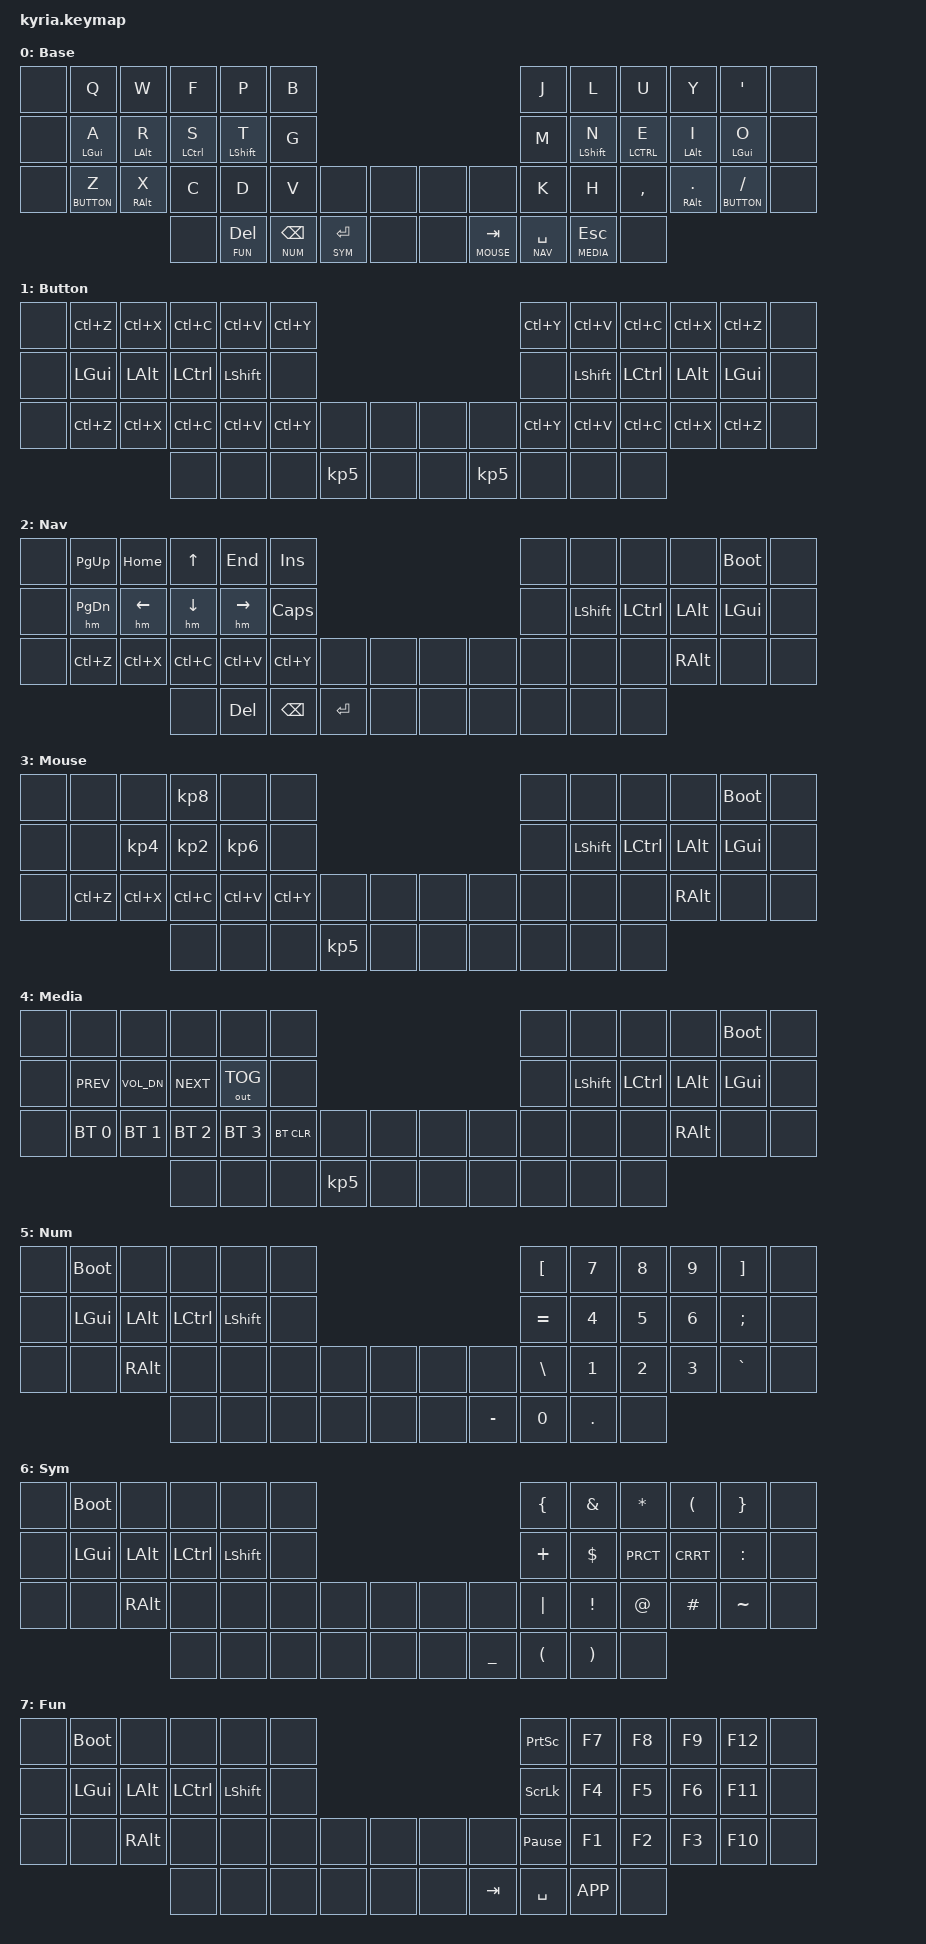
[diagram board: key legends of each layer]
/*
 * Copyright (c) 2020 The ZMK Contributors
 *
 * SPDX-License-Identifier: MIT
 */

#include <behaviors.dtsi>
#include <dt-bindings/zmk/bt.h>
#include <dt-bindings/zmk/keys.h>

// LAYER DEFINITIONS //
#define BASE   0
#define BUTTON 1
#define NAV    2
#define MOUSE  3
#define MEDIA  4
#define NUM    5
#define SYM    6
#define FUN    7

// CUSTOM KEY DEFINITIONS //
#define U_RDO &kp LC(Y) // WINDOWS redo
#define U_PST &kp LC(V) // WINDOWS paste
#define U_CPY &kp LC(C) // WINDOWS copy
#define U_CUT &kp LC(X) // WINDOWS cut
#define U_UND &kp LC(Z) // WINDOWS undo

#define U_BTN1 &kp KP_N5
#define U_BTN2 &none
#define U_BTN3 &none
#define U_MS_D &kp KP_N2
#define U_MS_L &kp KP_N4
#define U_MS_R &kp KP_N6
#define U_MS_U &kp KP_N8
#define U_WH_D &none
#define U_WH_L &none
#define U_WH_R &none
#define U_WH_U &none

// HOME ROW MOD CUSTOMIZATIONS //
#define U_TAPPING_TERM 200
#define U_TIMEOUT 50

/*                            KEY POSITIONS
  ╭─────────────-────────-─╮                 ╭────────────────────────╮
  │  0   1   2   3   4   5 │                 │  6   7   8   9  10  11 │
  │ 12  13  14  15  16  17 ╰───────╮ ╭───────╯ 18  19  20  21  22  23 │
  │ 24  25  26  27  28  29  30  31 │ │ 32  33  34  35  36  37  38  39 │
  ╰───────────╮ 40  41  42  43  44 │ │ 45  46  47  48  49 ╭───────────╯
              ╰────────────────────╯ ╰────────────────────╯            
*/

/ {
  behaviors {
    hm: homerow_mods {
      compatible = "zmk,behavior-hold-tap";
      label = "HOMEROW_MODS";
      #binding-cells = <2>;
      tapping_term_ms = <U_TAPPING_TERM>;
      flavor = "tap-preferred";
      bindings = <&kp>, <&kp>;
    };
  };

  combos {        
        compatible = "zmk,combos";        
        combo_btc {            
            timeout-ms = <U_TIMEOUT>;            
            key-positions = <0 12>;            
            bindings = <&bt BT_CLR>;  
        }; 
        combo_min2 {            
            timeout-ms = <U_TIMEOUT>;            
            key-positions = <3 4>;            
            bindings = <&kp MINUS>;  
        }; 
    
        combo_quot2 { 
            timeout-ms = <U_TIMEOUT>;             
            key-positions = <27 28>;            
            bindings = <&kp QUOT>;  
        };
    };


    keymap {
        compatible = "zmk,keymap";

        BASE_layer {
              label = "Base"; //MIRYOKU_ALTERNATIVES_BASE_COLEMAK_DH_FLIP

            /*                                                  BASE LAYER
            ╭──────────────────────────────────────────╮                         ╭──────────────────────────────────────────╮
            │ NONE  Q         W      F       P       B │                         │ J  L       U       Y      '         NONE │
            │ NONE  A|WIN     R|ALT  S|CTRL  T|SHFT  G ╰───────────╮ ╭───────────╯ M  N|SHFT  E|CTRL  I|ALT  O|WIN     NONE │
            │ NONE  Z|BUTTON  X|ALT  C       D       V  NONE  NONE │ │ NONE  NONE  K  H       ,       .|ALT  /|BUTTON  NONE │
            ╰───────────╮   NONE  DEL|FUN  BSPC|NUM  RET|SYM  NONE │ │ NONE  TAB|MOUSE  SPC|NAV  ESC|MEDIA  NONE ╭──────────╯
                        ╰──────────────────────────────────────────╯ ╰───────────────────────────────────────────╯            
            */

            bindings = <
                &none  &kp Q             &kp W              &kp F              &kp P              &kp B                                                          &kp J               &kp L               &kp U               &kp Y               &kp SQT           &none
                &none  &hm LGUI A        &hm LALT R         &hm LCTRL S        &hm LSHFT T        &kp G                                                          &kp M               &hm LSHFT N         &LCTRL E            &hm LALT I          &hm LGUI O        &none
                &none  &lt BUTTON Z      &hm RALT X         &kp C              &kp D              &kp V         &none        &none     &none      &none          &kp K               &kp H               &kp COMMA           &hm RALT DOT        &lt BUTTON SLASH  &none
                                                            &none              &lt FUN DEL        &lt NUM BSPC  &lt SYM RET  &none     &none      &lt MOUSE TAB  &lt NAV SPC         &lt MEDIA ESC       &none             
            >; 
                                           
        };                                       
        BUTTON_layer {                                       
              label = "Button"; //MIRYOKU_ALTERNATIVES_BUTTON                                      
            bindings = <                                       
                &none  U_UND             U_CUT              U_CPY              U_PST              U_RDO                                                          U_RDO               U_PST               U_CPY               U_CUT               U_UND             &none
                &none  &kp LGUI          &kp LALT           &kp LCTRL          &kp LSHFT          &none                                                          &none               &kp LSHFT           &kp LCTRL           &kp LALT            &kp LGUI          &none
                &none  U_UND             U_CUT              U_CPY              U_PST              U_RDO         &none        &none     &none      &none          U_RDO               U_PST               U_CPY               U_CUT               U_UND             &none
                                                            &none              U_BTN2             U_BTN3        U_BTN1       &none     &none      U_BTN1         U_BTN3              U_BTN2              &none
            >;        
        };  
        NAV_layer {  
            label = "Nav";  //MIRYOKU_ALTERNATIVES_NAV_INVERTEDT_FLIP
            bindings = <  
                &none  &kp PG_UP         &kp HOME           &kp UP             &kp END            &kp INS                                                        &none               &none               &none               &none               &bootloader      &none
                &none  &hm PG_DN         &hm LEFT           &hm DOWN           &hm RIGHT          &kp CAPS                                                       &none               &kp LSHFT           &kp LCTRL           &kp LALT            &kp LGUI         &none
                &none  U_UND             U_CUT              U_CPY              U_PST              U_RDO         &none        &none     &none      &none          &none               &none               &none               &kp RALT            &none            &none
                                                            &none              &kp DEL            &kp BSPC      &kp RET      &none     &none      &none          &none               &none               &none    
            >;      
        };      
        MOUSE_layer {      
            label = "Mouse"; //MIRYOKU_ALTERNATIVES_MOUSE_INVERTEDT_FLIP     
            bindings = <       
                &none  U_WH_U            U_WH_L             U_MS_U             U_WH_R             &none                                                          &none               &none               &none               &none               &bootloader      &none   
                &none  U_WH_D            U_MS_L             U_MS_D             U_MS_R             &none                                                          &none               &kp LSHFT           &kp LCTRL           &kp LALT            &kp LGUI         &none   
                &none  U_UND             U_CUT              U_CPY              U_PST              U_RDO         &none        &none     &none      &none          &none               &none               &none               &kp RALT            &none            &none   
                                                            &none              U_BTN2             U_BTN3        U_BTN1       &none     &none      &none          &none               &none               &none    
            >;      
        };      
        MEDIA_layer {      
            label = "Media"; //MIRYOKU_ALTERNATIVES_MEDIA_INVERTEDT_FLIP     
            bindings = <       
                &none  &none             &none              &none              &none              &none                                                          &none               &none               &none               &none               &bootloader      &none   
                &none  &kp C_PREV        &kp C_VOL_DN       &kp C_NEXT         &out OUT_TOG       &none                                                          &none               &kp LSHFT           &kp LCTRL           &kp LALT            &kp LGUI         &none   
                &none  &bt BT_SEL 0      &bt BT_SEL 1       &bt BT_SEL 2       &bt BT_SEL 3       &bt BT_CLR    &none       &none      &none      &none          &none               &none               &none               &kp RALT            &none            &none   
                                                            &none              U_BTN2             U_BTN3        U_BTN1      &none      &none      &none          &none               &none               &none    
            >;      
        };      
        NUM_layer {      
            label = "Num";  //MIRYOKU_ALTERNATIVES_NUM_FLIP    
            bindings = <      
                &none  &bootloader       &none              &none              &none              &none                                                          &kp LBKT            &kp NUM_7           &kp NUM_8           &kp NUM_9           &kp RBKT         &none   
                &none  &kp LGUI          &kp LALT           &kp LCTRL          &kp LSHFT          &none                                                          &kp EQL             &kp NUM_4           &kp NUM_5           &kp NUM_6           &kp SEMI         &none   
                &none  &none             &kp RALT           &none              &none              &none          &none       &none    &none     &none            &kp BSLH            &kp NUM_1           &kp NUM_2           &kp NUM_3           &kp GRAVE        &none   
                                                            &none              &none              &none          &none       &none    &none     &kp MINUS        &kp NUM_0           &kp DOT             &none    
            >;     
        };     
        SYM_layer {     
            label = "Sym";  //MIRYOKU_ALTERNATIVES_SYM_FLIP   
            bindings = <      
                &none  &bootloader       &none              &none              &none              &none                                                          &kp LBRC            &kp AMPS            &kp ASTRK           &kp LPAR            &kp RBRC         &none   
                &none  &kp LGUI          &kp LALT           &kp LCTRL          &kp LSHFT          &none                                                          &kp PLUS            &kp DLLR            &kp PRCT            &kp CRRT            &kp COLON        &none   
                &none  &none             &kp RALT           &none              &none              &none          &none       &none    &none     &none            &kp PIPE            &kp EXCL            &kp AT              &kp HASH            &kp TILDE        &none   
                                                            &none              &none              &none          &none       &none    &none     &kp UNDER        &kp LPAR            &kp RPAR            &none    
            >;     
        };     
        FUN_layer {     
            label = "Fun"; //MIRYOKU_ALTERNATIVES_FUN_FLIP    
            bindings = <      
                &none  &bootloader       &none              &none              &none              &none                                                          &kp PSCRN           &kp F7              &kp F8              &kp F9              &kp F12          &none   
                &none  &kp LGUI          &kp LALT           &kp LCTRL          &kp LSHFT          &none                                                          &kp SLCK            &kp F4              &kp F5              &kp F6              &kp F11          &none   
                &none  &none             &kp RALT           &none              &none              &none          &none       &none    &none     &none            &kp PAUSE_BREAK     &kp F1              &kp F2              &kp F3              &kp F10          &none   
                                                            &none              &none              &none          &none       &none    &none     &kp TAB          &kp SPC             &kp K_APP           &none
            >;
        };
    };
};
